# G32M3101 register map
File version: 1.0
CPU: CM0+ r0p1, little endian, MPU, no FPU, 2 interrupt priority bits
Registers are 32-bit, read-write, reset 0x0 unless marked. A register's access mark holds for its fields unless they carry their own. Offsets are from the block's base; [hi:lo] are bit positions; {n}, {i} and the like mark numbered series.

## BTMR — Base timer
Base 0x40002000
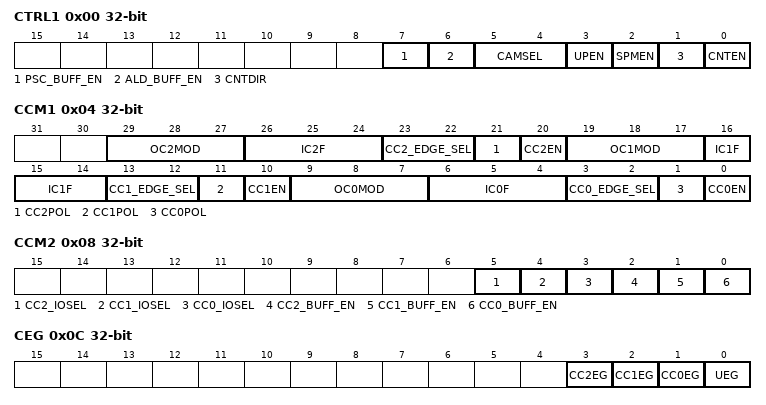
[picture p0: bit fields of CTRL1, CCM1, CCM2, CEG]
0x00 CTRL1 — control register 1
  [7] PSC_BUFF_EN — PSC preload enable
  [6] ALD_BUFF_EN — Auto-reload Preload Enable
  [5:4] CAMSEL — Choose center alignment mode
  [3] UPEN — Update Disable
  [2] SPMEN — Single Pulse Mode Enable
  [1] CNTDIR — Counter Direction
  [0] CNTEN — Timer enable
0x04 CCM1 — capture/compare mode register 1
  [29:27] OC2MOD — Output Compare Channel 2 Mode
  [26:24] IC2F — Input filter coefficients
  [23:22] CC2_EDGE_SEL — Capture Effective Edges
  [21] CC2POL — Capture/Compare Channel2 Output Polarity Configure
  [20] CC2EN — Capture/compare enable
  [19:17] OC1MOD — Output Compare Channel 1 Mode
  [16:14] IC1F — Input filter coefficients
  [13:12] CC1_EDGE_SEL — Capture Effective Edges
  [11] CC1POL — Capture/Compare Channel1 Output Polarity Configure
  [10] CC1EN — Capture/compare enable
  [9:7] OC0MOD — Output Compare Channel 0 Mode
  [6:4] IC0F — Input filter coefficients
  [3:2] CC0_EDGE_SEL — Capture Effective Edges
  [1] CC0POL — Capture/Compare Channel0 Output Polarity Configure
  [0] CC0EN — Capture/compare enable
0x08 CCM2 — capture/compare mode register 2
  [5] CC2_IOSEL
  [4] CC1_IOSEL
  [3] CC0_IOSEL
  [2] CC2_BUFF_EN
  [1] CC1_BUFF_EN
  [0] CC0_BUFF_EN — /
0x0C CEG wo — event generation register
  [3] CC2EG — Capture/compare 2 generation
  [2] CC1EG — Capture/compare 1 generation
  [1] CC0EG — Capture/compare 0 generation
  [0] UEG — Update generation
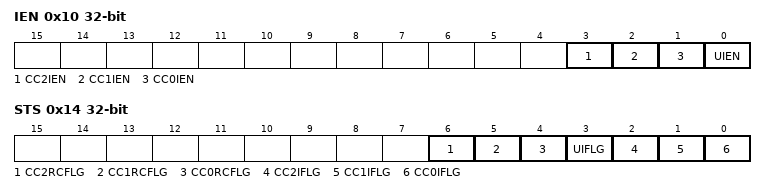
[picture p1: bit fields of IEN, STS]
0x10 IEN — interrupt enable register
  [3] CC2IEN — Capture/Compare 2 interrupt enable
  [2] CC1IEN — Capture/compare 1 interrupt enable
  [1] CC0IEN — Capture/compare 0 interrupt enable
  [0] UIEN — Update interrupt enable
0x14 STS — status register
  [6] CC2RCFLG — Captuer/Compare Channel2 Repetition Capture Flag
  [5] CC1RCFLG — Captuer/Compare Channel1 Repetition Capture Flag
  [4] CC0RCFLG — Captuer/Compare Channel0 Repetition Capture Flag
  [3] UIFLG — Update interrupt flag
  [2] CC2IFLG — Capture/Compare 2 interrupt flag
  [1] CC1IFLG — Capture/compare 1 interrupt flag
  [0] CC0IFLG — Capture/compare 0 interrupt flag
0x18 CNT — counter
  [15:0] CNT — Counter Value
0x1C PSC — prescaler
  [15:0] PSC — Prescaler value
0x20 AUTORLD reset 0xFFFF — auto-reload register
  [15:0] AUTORLD — Auto Reload Value
{0x24+4i} CC{i} (i=0..2) — capture/compare register {i}
  [15:0] CC{i} — Capture/Compare {i} value

## LPTMR — Low-power timer
Base 0x4000A000
0x00 CTRL — Control register
  [0] EN — Module enablement
0x04 PSC reset 0xF — Prescaler register
  [5:0] PSC — Prescaler divider
0x08 WUPV reset 0xFFFF — Reload register
  [15:0] WUPV — Awakening Value
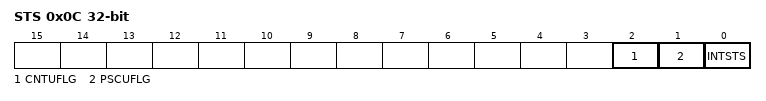
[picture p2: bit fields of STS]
0x0C STS ro — Status register
  [2] CNTUFLG — Reload value update indication, automatically reset by hardware after update.
  [1] PSCUFLG — PS value update indicator, hardware automatically resets after update.
  [0] INTSTS — Status Register, read SR register clear.
0x10 CNT ro — Counter register
  [15:0] CNT — Counter Value

## SPI — Serial peripheral interface
Base 0x40003000
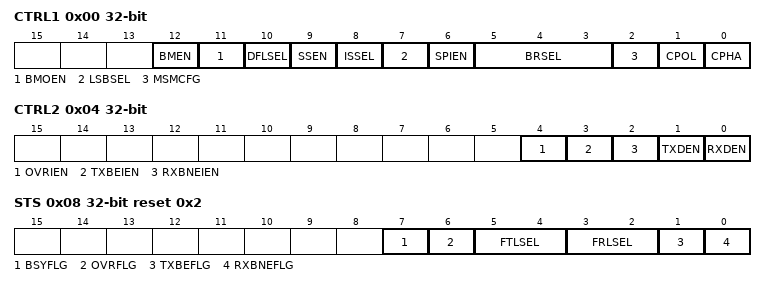
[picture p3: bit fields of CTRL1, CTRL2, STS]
0x00 CTRL1 — control register 1
  [12] BMEN — Bidirectional data mode enable
  [11] BMOEN — Output enable in bidirectional mode
  [10] DFLSEL — Receive only
  [9] SSEN — Software slave management
  [8] ISSEL — Internal slave select
  [7] LSBSEL — Frame format
  [6] SPIEN — SPI enable
  [5:3] BRSEL — Baud rate control
  [2] MSMCFG — Master selection
  [1] CPOL — Clock polarity
  [0] CPHA — Clock phase
0x04 CTRL2 — control register 2
  [4] OVRIEN — Overflow
  [3] TXBEIEN — Tx buffer empty interrupt enable
  [2] RXBNEIEN — SS output enable
  [1] TXDEN — Tx buffer DMA enable
  [0] RXDEN — Rx buffer DMA enable
0x08 STS ro reset 0x2 — status register
  [7] BSYFLG — Busy flag
  [6] OVRFLG — Overrun flag
  [5:4] FTLSEL — FTLVL
  [3:2] FRLSEL — FRLVL
  [1] TXBEFLG — Transmit buffer empty
  [0] RXBNEFLG — Receive buffer not empty
0x0C DATA
  [15:0] DATA
